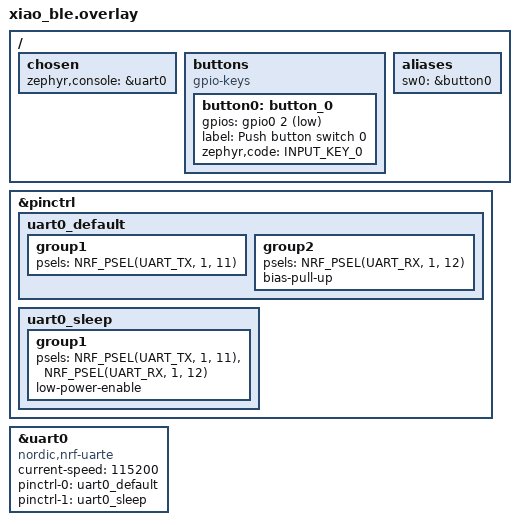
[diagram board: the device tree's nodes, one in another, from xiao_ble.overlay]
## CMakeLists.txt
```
# SPDX-License-Identifier: Apache-2.0

cmake_minimum_required(VERSION 3.20.0)

#set(BOARD nrf52840dk/nrf52840)
set(BOARD xiao_ble)

find_package(Zephyr REQUIRED HINTS $ENV{ZEPHYR_BASE})
project(nrf_system_off)

target_sources(app PRIVATE src/main.c)
target_sources_ifdef(CONFIG_APP_RETENTION app PRIVATE src/retained.c)

# zephyr_compile_options(-save-temps)
```

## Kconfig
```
# Copyright (c) 2021 Nordic Semiconductor ASA
# SPDX-License-Identifier: Apache-2.0

mainmenu "nrf52-series SYSTEM_OFF Demo"

menu "SYSTEM_OFF Demo Options"

config APP_RETENTION
	bool "Memory retention while in 'system-off' state"
	depends on SOC_COMPATIBLE_NRF52X && CRC
	help
	  On some Nordic chips this application supports retaining
	  memory while in system off.  Select this to enable the
	  feature.

rsource "./Kconfig.xiao_ble"

endmenu

source "Kconfig.zephyr"
```

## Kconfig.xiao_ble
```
# Copyright (c) 2024 Callender Consulting LLC
# SPDX-License-Identifier: Apache-2.0

menu "SEEED XIAO_BLE Options "

config XIAO_BLE_BUTTON_PIN
	int "Button GPIO pin number"
	depends on BOARD_XIAO_BLE
	range 2 4
	default 2
	help
	  The XIAO BLE board doesn't have a user-button,
	  so a GPIO pin must be defined: GPIO0_n, n = pin number.

endmenu
```

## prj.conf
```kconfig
CONFIG_PM_DEVICE=y
CONFIG_GPIO=y
CONFIG_CRC=y
CONFIG_POWEROFF=y

#------------------------------------------------
# Logging interface: UART or RTT.
# By default logging will be to UART.
# For RTT logging (JLink or Ozone), uncomment 
# indicated section below.
#
CONFIG_LOG=y
CONFIG_LOG_PRINTK=y
CONFIG_LOG_MODE_IMMEDIATE=y

CONFIG_LOG_BACKEND_SHOW_COLOR=n
CONFIG_LOG_BACKEND_FORMAT_TIMESTAMP=n

# Uncomment this section for RTT support
CONFIG_USE_SEGGER_RTT=y
CONFIG_LOG_BACKEND_RTT=y
#CONFIG_LOG_BACKEND_UART=n
```

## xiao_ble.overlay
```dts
/* 
 *  Copyright (c) 2024 Callender-Consulting
 *
 *  SPDX-License-Identifier: Apache-2.0
 */

/*
 *  Add button0 (sw0) to XIAO_BLE DTS defines
 */

/ {
    chosen {
        zephyr,console = &uart0;
    };

    buttons {
        compatible = "gpio-keys";
        button0: button_0 {
            gpios = <&gpio0 2 (GPIO_PULL_UP | GPIO_ACTIVE_LOW)>;
            label = "Push button switch 0";
            zephyr,code = <INPUT_KEY_0>;
        };
    };

    aliases {
        sw0 = &button0;
    };
};

&pinctrl {
    uart0_default: uart0_default {
        group1 {
            psels = <NRF_PSEL(UART_TX, 1, 11)>;
        };
        group2 {
            psels = <NRF_PSEL(UART_RX, 1, 12)>;
            bias-pull-up;
        };
    };

    uart0_sleep: uart0_sleep {
        group1 {
            psels = <NRF_PSEL(UART_TX, 1, 11)>,
                    <NRF_PSEL(UART_RX, 1, 12)>;
            low-power-enable;
        };
    };
};    

&uart0 {
    compatible = "nordic,nrf-uarte";
    status = "okay";
    current-speed = <115200>;
    pinctrl-0 = <&uart0_default>;
    pinctrl-1 = <&uart0_sleep>;
    pinctrl-names = "default", "sleep";
};
```

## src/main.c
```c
/*
 * Copyright (c) 2019 Nordic Semiconductor ASA
 *
 * SPDX-License-Identifier: Apache-2.0
 */

#include "retained.h"

#include <inttypes.h>
#include <stdio.h>

#include <zephyr/device.h>
#include <zephyr/drivers/gpio.h>
#include <zephyr/kernel.h>
#include <zephyr/pm/device.h>
#include <zephyr/sys/poweroff.h>
#include <zephyr/sys/util.h>

#define LOG_LEVEL CONFIG_LOG_DEFAULT_LEVEL
#include <zephyr/logging/log.h>
LOG_MODULE_REGISTER(sys_off);

static const struct gpio_dt_spec sw0 = GPIO_DT_SPEC_GET(DT_ALIAS(sw0), gpios);

int main(void)
{
	int rc;
	const struct device *const cons = DEVICE_DT_GET(DT_CHOSEN(zephyr_console));

	if (!device_is_ready(cons)) {
		LOG_ERR("%s: device not ready.", cons->name);
		return 0;
	}

	LOG_INF("%s system-off demo", CONFIG_BOARD);

	if (IS_ENABLED(CONFIG_APP_RETENTION)) {
		bool retained_ok = retained_validate();

		/* Increment for this boot attempt and update. */
		retained.boots += 1;
		retained_update();

		LOG_INF("Retained data: %s", retained_ok ? "valid" : "INVALID");
		LOG_INF("Boot count: %u", retained.boots);
		LOG_INF("Off count: %u", retained.off_count);
		LOG_INF("Active Ticks: %" PRIu64, retained.uptime_sum);
	} else {
		LOG_INF("Retained data not supported");
	}

	/* configure sw0 as input, interrupt as level active to allow wake-up */
	rc = gpio_pin_configure_dt(&sw0, GPIO_INPUT);
	if (rc < 0) {
		LOG_ERR("Could not configure sw0 GPIO (%d)", rc);
		return 0;
	}

	rc = gpio_pin_interrupt_configure_dt(&sw0, GPIO_INT_LEVEL_ACTIVE);
	if (rc < 0) {
		LOG_ERR("Could not configure sw0 GPIO interrupt (%d)", rc);
		return 0;
	}

	LOG_INF("Entering system off; press sw0 to restart");

	rc = pm_device_action_run(cons, PM_DEVICE_ACTION_SUSPEND);
	if (rc < 0) {
		LOG_ERR("Could not suspend console (%d)", rc);
		return 0;
	}

	if (IS_ENABLED(CONFIG_APP_RETENTION)) {
		/* Update the retained state */
		retained.off_count += 1;
		retained_update();
	}

	sys_poweroff();

	return 0;
}
```
